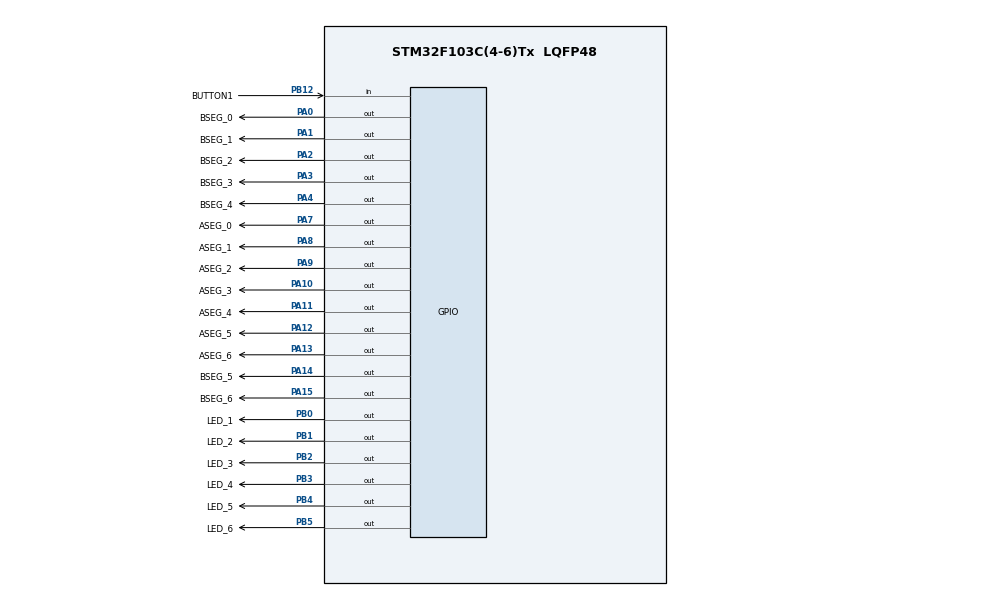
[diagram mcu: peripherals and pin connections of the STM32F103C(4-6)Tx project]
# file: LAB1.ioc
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Mcu.Family=STM32F1
Mcu.Name=STM32F103C(4-6)Tx
Mcu.Package=LQFP48
NVIC.PriorityGroup=NVIC_PRIORITYGROUP_4
NVIC.TIM3_IRQn=true\:0\:0\:false\:false\:true\:true\:true
PA0-WKUP.GPIO_Label=BSEG_0
PA0-WKUP.Signal=GPIO_Output
PA1.GPIO_Label=BSEG_1
PA1.Signal=GPIO_Output
PA10.GPIO_Label=ASEG_3
PA10.Signal=GPIO_Output
PA11.GPIO_Label=ASEG_4
PA11.Signal=GPIO_Output
PA12.GPIO_Label=ASEG_5
PA12.Signal=GPIO_Output
PA13.GPIO_Label=ASEG_6
PA13.Signal=GPIO_Output
PA14.GPIO_Label=BSEG_5
PA14.Signal=GPIO_Output
PA15.GPIO_Label=BSEG_6
PA15.Signal=GPIO_Output
PA2.GPIO_Label=BSEG_2
PA2.Signal=GPIO_Output
PA3.GPIO_Label=BSEG_3
PA3.Signal=GPIO_Output
PA4.GPIO_Label=BSEG_4
PA4.Signal=GPIO_Output
PA7.GPIO_Label=ASEG_0
PA7.Signal=GPIO_Output
PA8.GPIO_Label=ASEG_1
PA8.Signal=GPIO_Output
PA9.GPIO_Label=ASEG_2
PA9.Signal=GPIO_Output
PB0.GPIO_Label=LED_1
PB0.Signal=GPIO_Output
PB1.GPIO_Label=LED_2
PB1.Signal=GPIO_Output
PB12.GPIO_Label=BUTTON1
PB12.GPIO_PuPd=GPIO_PULLUP
PB12.Signal=GPIO_Input
PB2.GPIO_Label=LED_3
PB2.Signal=GPIO_Output
PB3.GPIO_Label=LED_4
PB3.Signal=GPIO_Output
PB4.GPIO_Label=LED_5
PB4.Signal=GPIO_Output
PB5.GPIO_Label=LED_6
PB5.Signal=GPIO_Output
ProjectManager.HeapSize=0x200
ProjectManager.StackSize=0x400
ProjectManager.TargetToolchain=STM32CubeIDE
RCC.APB1Freq_Value=8000000
RCC.APB2Freq_Value=8000000
TIM3.Period=9
TIM3.Prescaler=7999
VP_SYS_VS_ND.Mode=No_Debug
VP_TIM3_VS_ClockSourceINT.Mode=Internal
board=custom

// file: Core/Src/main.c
/* USER CODE BEGIN Header */
/**
  ******************************************************************************
  * @file           : main.c
  * @brief          : Main program body
  ******************************************************************************
  * @attention
  *
  * <h2><center>&copy; Copyright (c) 2024 STMicroelectronics.
  * All rights reserved.</center></h2>
  *
  * This software component is licensed by ST under BSD 3-Clause license,
  * the "License"; You may not use this file except in compliance with the
  * License. You may obtain a copy of the License at:
  *                        opensource.org/licenses/BSD-3-Clause
  *
  ******************************************************************************
  */
/* USER CODE END Header */
#include "main.h"

/* USER CODE BEGIN Includes */
#include "exercise3.h"
#include "global.h"
#include "automatic.h"
#include "manual.h"
/* USER CODE END Includes */

TIM_HandleTypeDef htim3;

void SystemClock_Config(void);
static void MX_GPIO_Init(void);
static void MX_TIM3_Init(void);

int main(void)
{

  /* MCU Configuration--------------------------------------------------------*/

  /* Reset of all peripherals, Initializes the Flash interface and the Systick. */
  HAL_Init();

  /* Configure the system clock */
  SystemClock_Config();

  /* Initialize all configured peripherals */
  MX_GPIO_Init();
  MX_TIM3_Init();

  /* Infinite loop */
  while (1)
  {

    /* USER CODE BEGIN 3 */
	  exercise3_run();
	  HAL_Delay(1000);
  }
  /* USER CODE END 3 */
}

void SystemClock_Config(void)
{
  RCC_OscInitTypeDef RCC_OscInitStruct = {0};
  RCC_ClkInitTypeDef RCC_ClkInitStruct = {0};

  /** Initializes the RCC Oscillators according to the specified parameters
  * in the RCC_OscInitTypeDef structure.
  */
  RCC_OscInitStruct.OscillatorType = RCC_OSCILLATORTYPE_HSI;
  RCC_OscInitStruct.HSIState = RCC_HSI_ON;
  RCC_OscInitStruct.HSICalibrationValue = RCC_HSICALIBRATION_DEFAULT;
  RCC_OscInitStruct.PLL.PLLState = RCC_PLL_NONE;
  if (HAL_RCC_OscConfig(&RCC_OscInitStruct) != HAL_OK)
  {
    Error_Handler();
  }
  /** Initializes the CPU, AHB and APB buses clocks
  */
  RCC_ClkInitStruct.ClockType = RCC_CLOCKTYPE_HCLK|RCC_CLOCKTYPE_SYSCLK
                              |RCC_CLOCKTYPE_PCLK1|RCC_CLOCKTYPE_PCLK2;
  RCC_ClkInitStruct.SYSCLKSource = RCC_SYSCLKSOURCE_HSI;
  RCC_ClkInitStruct.AHBCLKDivider = RCC_SYSCLK_DIV1;
  RCC_ClkInitStruct.APB1CLKDivider = RCC_HCLK_DIV1;
  RCC_ClkInitStruct.APB2CLKDivider = RCC_HCLK_DIV1;

  if (HAL_RCC_ClockConfig(&RCC_ClkInitStruct, FLASH_LATENCY_0) != HAL_OK)
  {
    Error_Handler();
  }
}

static void MX_TIM3_Init(void)
{

  TIM_ClockConfigTypeDef sClockSourceConfig = {0};
  TIM_MasterConfigTypeDef sMasterConfig = {0};

  htim3.Instance = TIM3;
  htim3.Init.Prescaler = 7999;
  htim3.Init.CounterMode = TIM_COUNTERMODE_UP;
  htim3.Init.Period = 9;
  htim3.Init.ClockDivision = TIM_CLOCKDIVISION_DIV1;
  htim3.Init.AutoReloadPreload = TIM_AUTORELOAD_PRELOAD_DISABLE;
  if (HAL_TIM_Base_Init(&htim3) != HAL_OK)
  {
    Error_Handler();
  }
  sClockSourceConfig.ClockSource = TIM_CLOCKSOURCE_INTERNAL;
  if (HAL_TIM_ConfigClockSource(&htim3, &sClockSourceConfig) != HAL_OK)
  {
    Error_Handler();
  }
  sMasterConfig.MasterOutputTrigger = TIM_TRGO_RESET;
  sMasterConfig.MasterSlaveMode = TIM_MASTERSLAVEMODE_DISABLE;
  if (HAL_TIMEx_MasterConfigSynchronization(&htim3, &sMasterConfig) != HAL_OK)
  {
    Error_Handler();
  }

}

static void MX_GPIO_Init(void)
{
  GPIO_InitTypeDef GPIO_InitStruct = {0};

  /* GPIO Ports Clock Enable */
  __HAL_RCC_GPIOA_CLK_ENABLE();
  __HAL_RCC_GPIOB_CLK_ENABLE();

  /*Configure GPIO pin Output Level */
  HAL_GPIO_WritePin(GPIOA, BSEG_0_Pin|BSEG_1_Pin|BSEG_2_Pin|BSEG_3_Pin
                          |BSEG_4_Pin|ASEG_0_Pin|ASEG_1_Pin|ASEG_2_Pin
                          |ASEG_3_Pin|ASEG_4_Pin|ASEG_5_Pin|ASEG_6_Pin
                          |BSEG_5_Pin|BSEG_6_Pin, GPIO_PIN_RESET);

  /*Configure GPIO pin Output Level */
  HAL_GPIO_WritePin(GPIOB, LED_1_Pin|LED_2_Pin|LED_3_Pin|LED_4_Pin
                          |LED_5_Pin|LED_6_Pin, GPIO_PIN_RESET);

  /*Configure GPIO pins : BSEG_0_Pin BSEG_1_Pin BSEG_2_Pin BSEG_3_Pin
                           BSEG_4_Pin ASEG_0_Pin ASEG_1_Pin ASEG_2_Pin
                           ASEG_3_Pin ASEG_4_Pin ASEG_5_Pin ASEG_6_Pin
                           BSEG_5_Pin BSEG_6_Pin */
  GPIO_InitStruct.Pin = BSEG_0_Pin|BSEG_1_Pin|BSEG_2_Pin|BSEG_3_Pin
                          |BSEG_4_Pin|ASEG_0_Pin|ASEG_1_Pin|ASEG_2_Pin
                          |ASEG_3_Pin|ASEG_4_Pin|ASEG_5_Pin|ASEG_6_Pin
                          |BSEG_5_Pin|BSEG_6_Pin;
  GPIO_InitStruct.Mode = GPIO_MODE_OUTPUT_PP;
  GPIO_InitStruct.Pull = GPIO_NOPULL;
  GPIO_InitStruct.Speed = GPIO_SPEED_FREQ_LOW;
  HAL_GPIO_Init(GPIOA, &GPIO_InitStruct);

  /*Configure GPIO pins : LED_1_Pin LED_2_Pin LED_3_Pin LED_4_Pin
                           LED_5_Pin LED_6_Pin */
  GPIO_InitStruct.Pin = LED_1_Pin|LED_2_Pin|LED_3_Pin|LED_4_Pin
                          |LED_5_Pin|LED_6_Pin;
  GPIO_InitStruct.Mode = GPIO_MODE_OUTPUT_PP;
  GPIO_InitStruct.Pull = GPIO_NOPULL;
  GPIO_InitStruct.Speed = GPIO_SPEED_FREQ_LOW;
  HAL_GPIO_Init(GPIOB, &GPIO_InitStruct);

  /*Configure GPIO pin : BUTTON1_Pin */
  GPIO_InitStruct.Pin = BUTTON1_Pin;
  GPIO_InitStruct.Mode = GPIO_MODE_INPUT;
  GPIO_InitStruct.Pull = GPIO_PULLUP;
  HAL_GPIO_Init(BUTTON1_GPIO_Port, &GPIO_InitStruct);

}

void Error_Handler(void)
{
  __disable_irq();
  while (1)
  {
  }
}

/************************ (C) COPYRIGHT STMicroelectronics *****END OF FILE****/
